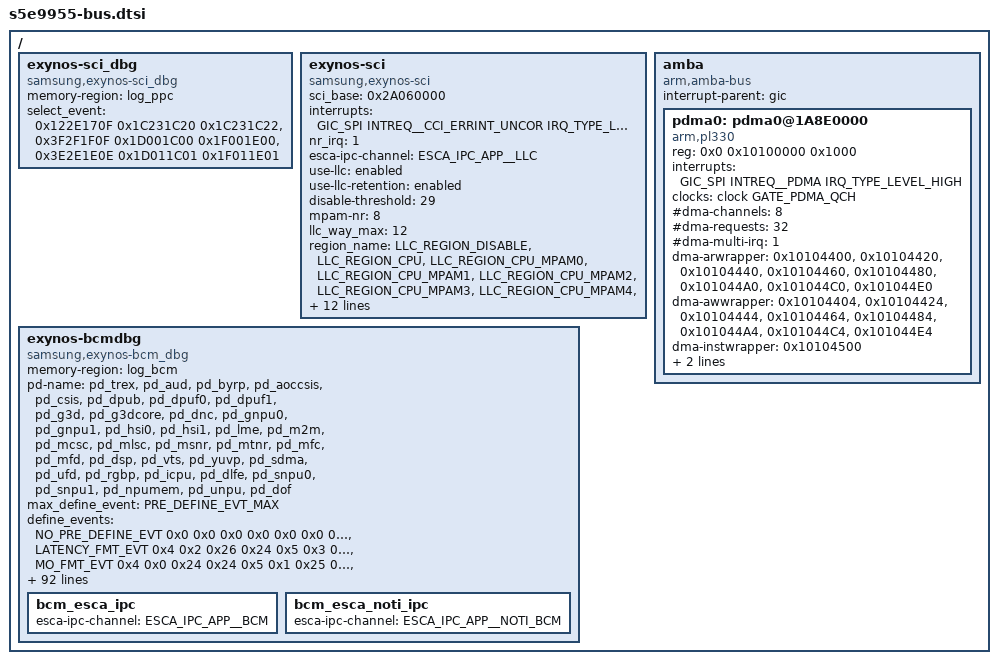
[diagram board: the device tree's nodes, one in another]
/* SAMSUNG EXYNOS SoC BUS device tree source
 *
 * Copyright (c) 2024 Samsung Electronics Co., Ltd.
 *		http://www.samsung.com
 *
 * SAMSUNG EXYNOS SoC BUS device nodes are listed in this file.
 * EXYNOS based board files should include this file.
 *
 * This program is free software; you can redistribute it and/or modify
 * it under the terms of the GNU General Public License version 2 as
 * published by the Free Software Foundation.
 *
 */

#include <dt-bindings/soc/samsung/exynos-bcm_dbg.h>
#include "s5e9955-bts.dtsi"
/ {
	exynos-sci_dbg {
		compatible = "samsung,exynos-sci_dbg";
		memory-region = <&log_ppc>;
		/* SCI_EVENT_SEL, DebugSrc10, DebugSrc32 */
		select_event = <0x122E170F 0x1C231C20 0x1C231C22>,
			     <0x3F2F1F0F 0x1D001C00 0x1F001E00>,
			     <0x3E2E1E0E 0x1D011C01 0x1F011E01>;
	};

	exynos-sci {
		compatible = "samsung,exynos-sci";
		sci_base = <0x2A060000>;
		interrupts = <GIC_SPI INTREQ__CCI_ERRINT_UNCOR IRQ_TYPE_LEVEL_HIGH>;
		nr_irq = <1>;
		esca-ipc-channel = <ESCA_IPC_APP__LLC>;
		use-llc = "enabled";
		use-llc-retention = "enabled";

		disable-threshold = <29>;
		mpam-nr = <8>;

		llc_way_max = <12>;

		region_name = "LLC_REGION_DISABLE",
			    "LLC_REGION_CPU",
			    "LLC_REGION_CPU_MPAM0",
			    "LLC_REGION_CPU_MPAM1",
			    "LLC_REGION_CPU_MPAM2",
			    "LLC_REGION_CPU_MPAM3",
			    "LLC_REGION_CPU_MPAM4",
			    "LLC_REGION_CPU_MPAM5",
			    "LLC_REGION_CPU_MPAM6",
			    "LLC_REGION_CPU_MPAM7",
			    "LLC_REGION_CALL",
			    "LLC_REGION_OFFLOAD",
			    "LLC_REGION_CPD2",
			    "LLC_REGION_CPCPU",
			    "LLC_REGION_DPU",
			    "LLC_REGION_ICPU",
			    "LLC_REGION_MFC0_DPB",
			    "LLC_REGION_MFC1_DPB",
			    "LLC_REGION_MFC0_INT",
			    "LLC_REGION_MFC1_INT",
			    "LLC_REGION_GDC",
			    "LLC_REGION_PROFILER",
			    "LLC_REGION_GPU",
			    "LLC_REGION_NPU0",
			    "LLC_REGION_NPU1",
			    "LLC_REGION_NPU2",
			    "LLC_REGION_DSP0",
			    "LLC_REGION_DSP1",
			    "LLC_REGION_CAM_MCFP",
			    "LLC_REGION_CAM_CSIS",
			    "LLC_REGION_CP_MAX_TP";
	};

	exynos-bcmdbg {
		compatible = "samsung,exynos-bcm_dbg";
		memory-region = <&log_bcm>;

		pd-name = "pd_trex", "pd_aud", "pd_byrp", "pd_aoccsis", "pd_csis", 
			"pd_dpub", "pd_dpuf0", "pd_dpuf1", "pd_g3d", "pd_g3dcore", "pd_dnc",
			"pd_gnpu0", "pd_gnpu1", "pd_hsi0", "pd_hsi1", "pd_lme", "pd_m2m", "pd_mcsc",
			"pd_mlsc", "pd_msnr", "pd_mtnr", "pd_mfc", "pd_mfd", "pd_dsp", "pd_vts", "pd_yuvp", "pd_sdma", "pd_ufd",
			"pd_rgbp", "pd_icpu", "pd_dlfe", "pd_snpu0", "pd_snpu1", "pd_npumem", "pd_unpu", "pd_dof";
		max_define_event = <PRE_DEFINE_EVT_MAX>;
		/* define_event_index ev0 ev1 ev2 ev3 ev4 ev5 ev6 ev7 */
		define_events = <NO_PRE_DEFINE_EVT	0x0  0x0  0x0  0x0  0x0  0x0  0x0  0x0>,
				<LATENCY_FMT_EVT	0x4  0x2  0x26 0x24 0x5  0x3  0x27 0x25>,
				<MO_FMT_EVT		0x4  0x0  0x24 0x24 0x5  0x1  0x25 0x25>,
				<BURST_LENGTH_FMT_EVT	0x4  0x2  0x4  0x26 0x5  0x3  0x5  0x27>,
				<REQ_BLOCK_FMT_EVT	0x2  0x10 0x10 0x26 0x3  0x11 0x11 0x27>,
				<DATA_BLOCK_FMT_EVT	0x4  0x12 0x12 0x6  0x5  0x13 0x13 0x14>,
				<REQ_TYPE_FMT_EVT	0x2  0x15 0x18 0x1B 0x3  0x16 0x19 0x1C>,
				<BW_DFP_FMT_EVT		0x4  0x2  0x2A 0x24 0x5  0x3  0x2B 0x25>,
				<BCM_CALC_FMT_EVT	0x4  0x5  0x26 0x24 0x0  0x1  0x27 0x25>;
		default_define_event = <LATENCY_FMT_EVT>;

		/* sm_id_mask sm_id_value */
		define_filter_id = <NO_PRE_DEFINE_EVT	0x0  0x0>,
				<LATENCY_FMT_EVT	0x0  0x0>,
				<MO_FMT_EVT		0x0  0x0>,
				<BURST_LENGTH_FMT_EVT	0x0  0x0>,
				<REQ_BLOCK_FMT_EVT	0x0  0x0>,
				<DATA_BLOCK_FMT_EVT	0x0  0x0>,
				<REQ_TYPE_FMT_EVT	0x0  0x0>,
				<BW_DFP_FMT_EVT		0x0  0x0>,
				<BCM_CALC_FMT_EVT	0x0  0x0>;
		/* ev0 ev1 ev2 ev3 ev4 ev5 ev6 ev7 */
		define_filter_id_active = <NO_PRE_DEFINE_EVT	0x0  0x0  0x0  0x0  0x0  0x0  0x0  0x0>,
					<LATENCY_FMT_EVT	0x0  0x0  0x0  0x0  0x0  0x0  0x0  0x0>,
					<MO_FMT_EVT		0x0  0x0  0x0  0x0  0x0  0x0  0x0  0x0>,
					<BURST_LENGTH_FMT_EVT	0x0  0x0  0x0  0x0  0x0  0x0  0x0  0x0>,
					<REQ_BLOCK_FMT_EVT	0x0  0x0  0x0  0x0  0x0  0x0  0x0  0x0>,
					<DATA_BLOCK_FMT_EVT	0x0  0x0  0x0  0x0  0x0  0x0  0x0  0x0>,
					<REQ_TYPE_FMT_EVT	0x0  0x0  0x0  0x0  0x0  0x0  0x0  0x0>,
					<BW_DFP_FMT_EVT		0x0  0x0  0x0  0x0  0x0  0x0  0x0  0x0>,
					<BCM_CALC_FMT_EVT	0x0  0x0  0x0  0x0  0x0  0x0  0x0  0x0>;
		/* sm_other_type0 sm_other_mask0 sm_other_value0 */
		define_filter_other_0 = <NO_PRE_DEFINE_EVT	0x0  0x0  0x0>,
					<LATENCY_FMT_EVT	0x0  0x0  0x0>,
					<MO_FMT_EVT		0x0  0x0  0x0>,
					<BURST_LENGTH_FMT_EVT	0x0  0x0  0x0>,
					<REQ_BLOCK_FMT_EVT	0x0  0x0  0x0>,
					<DATA_BLOCK_FMT_EVT	0x0  0x0  0x0>,
					<REQ_TYPE_FMT_EVT	0x0  0x0  0x0>,
					<BW_DFP_FMT_EVT		0x0  0x0  0x0>,
					<BCM_CALC_FMT_EVT	0x0  0x0  0x0>;
		/* sm_other_type1 sm_other_mask1 sm_other_value1 */
		define_filter_other_1 = <NO_PRE_DEFINE_EVT	0x0  0x0  0x0>,
					<LATENCY_FMT_EVT	0x0  0x0  0x0>,
					<MO_FMT_EVT		0x0  0x0  0x0>,
					<BURST_LENGTH_FMT_EVT	0x0  0x0  0x0>,
					<REQ_BLOCK_FMT_EVT	0x0  0x0  0x0>,
					<DATA_BLOCK_FMT_EVT	0x0  0x0  0x0>,
					<REQ_TYPE_FMT_EVT	0x0  0x0  0x0>,
					<BW_DFP_FMT_EVT		0x0  0x0  0x0>,
					<BCM_CALC_FMT_EVT	0x0  0x0  0x0>;
		/* ev0 ev1 ev2 ev3 ev4 ev5 ev6 ev7 */
		define_filter_other_active = <NO_PRE_DEFINE_EVT	0x0  0x0  0x0  0x0  0x0  0x0  0x0  0x0>,
					<LATENCY_FMT_EVT	0x0  0x0  0x0  0x0  0x0  0x0  0x0  0x0>,
					<MO_FMT_EVT		0x0  0x0  0x0  0x0  0x0  0x0  0x0  0x0>,
					<BURST_LENGTH_FMT_EVT	0x0  0x0  0x0  0x0  0x0  0x0  0x0  0x0>,
					<REQ_BLOCK_FMT_EVT	0x0  0x0  0x0  0x0  0x0  0x0  0x0  0x0>,
					<DATA_BLOCK_FMT_EVT	0x0  0x0  0x0  0x0  0x0  0x0  0x0  0x0>,
					<REQ_TYPE_FMT_EVT	0x0  0x0  0x0  0x0  0x0  0x0  0x0  0x0>,
					<BW_DFP_FMT_EVT		0x0  0x0  0x0  0x0  0x0  0x0  0x0  0x0>,
					<BCM_CALC_FMT_EVT	0x0  0x0  0x0  0x0  0x0  0x0  0x0  0x0>;
		/* peak_mask peak_id */
		define_sample_id = <NO_PRE_DEFINE_EVT	0x0  0x0>,
				<LATENCY_FMT_EVT	0x0  0x0>,
				<MO_FMT_EVT		0x0  0x0>,
				<BURST_LENGTH_FMT_EVT	0x0  0x0>,
				<REQ_BLOCK_FMT_EVT	0x0  0x0>,
				<DATA_BLOCK_FMT_EVT	0x0  0x0>,
				<REQ_TYPE_FMT_EVT	0x0  0x0>,
				<BW_DFP_FMT_EVT		0x0  0x0>,
				<BCM_CALC_FMT_EVT	0x0  0x0>;
		/* ev0 ev1 ev2 ev3 ev4 ev5 ev6 ev7 */
		define_sample_id_enable = <NO_PRE_DEFINE_EVT	0x0  0x0  0x0  0x0  0x0  0x0  0x0  0x0>,
					<LATENCY_FMT_EVT	0x0  0x0  0x1  0x0  0x0  0x0  0x1  0x0>,
					<MO_FMT_EVT		0x0  0x0  0x1  0x0  0x0  0x0  0x1  0x0>,
					<BURST_LENGTH_FMT_EVT	0x0  0x0  0x1  0x1  0x0  0x0  0x1  0x1>,
					<REQ_BLOCK_FMT_EVT	0x0  0x0  0x1  0x1  0x0  0x0  0x1  0x1>,
					<DATA_BLOCK_FMT_EVT	0x0  0x0  0x1  0x0  0x0  0x0  0x1  0x0>,
					<REQ_TYPE_FMT_EVT	0x0  0x0  0x0  0x0  0x0  0x0  0x0  0x0>,
					<BW_DFP_FMT_EVT		0x0  0x0  0x0  0x0  0x0  0x0  0x0  0x0>,
					<BCM_CALC_FMT_EVT	0x0  0x0  0x0  0x0  0x0  0x0  0x0  0x0>;

		bcm_cnt_nr = <8>;
		bcm_ip_nr = <86>;
		bcm_ip_print_nr = <10>;
		unused_bcm_ip = <21>, <81>, <85>;
		initial_bcm_run = <BCM_STOP>;
		/* msec (max 500msec) */
		initial_period = <1000>;
		initial_bcm_mode = <BCM_MODE_INTERVAL>;
		available_stop_owner = <PANIC_HANDLE CAMERA_DRIVER MODEM_IF ITMON_HANDLE>;
		halt_owner = <PANIC_HANDLE ITMON_HANDLE>;
		glb_auto_en = <0>;

		/* profiler infomation */
		bcm_calc_num_ip = <4>;
		bcm_calc_ip_idx = <1>, <5>, <45>, <49>;
		bcm_calc_ip_name = "CPUCL0_0", "G3D0", "IRPS0", "MIF0";
		bcm_calc_ip_cnt = <4>, <4>, <4>, <4>;
		bcm_calc_bus_width = <32>, <32>, <32>, <16>;
		bcm_calc_sample_time = <50>;
		perf_define_event = <BCM_CALC_FMT_EVT>;

		rtc_addr = <0x13900000>, <0x90>;

		bcm_esca_ipc {
			esca-ipc-channel = <ESCA_IPC_APP__BCM>;
		};
		bcm_esca_noti_ipc {
			esca-ipc-channel = <ESCA_IPC_APP__NOTI_BCM>;
		};
	};

	/* DMA */
	amba {
		#address-cells = <2>;
		#size-cells = <1>;
		compatible = "arm,amba-bus";
		interrupt-parent = <&gic>;
		ranges;
		pdma0: pdma0@1A8E0000 {
			compatible = "arm,pl330", "arm,primecell";
			reg = <0x0 0x10100000 0x1000>;
			interrupts = <GIC_SPI INTREQ__PDMA IRQ_TYPE_LEVEL_HIGH>;
			clocks = <&clock GATE_PDMA_QCH>;
			clock-names = "apb_pclk";
			#dma-cells = <1>;
			#dma-channels = <8>;
			#dma-requests = <32>;
			#dma-multi-irq = <1>;
			dma-arwrapper = <0x10104400>,
							<0x10104420>,
							<0x10104440>,
							<0x10104460>,
							<0x10104480>,
							<0x101044A0>,
							<0x101044C0>,
							<0x101044E0>;
			dma-awwrapper = <0x10104404>,
							<0x10104424>,
							<0x10104444>,
							<0x10104464>,
							<0x10104484>,
							<0x101044A4>,
							<0x101044C4>,
							<0x101044E4>;
			dma-instwrapper = <0x10104500>;
			dma-mask-bit = <36>;
			coherent-mask-bit = <36>;
		};
	};

};
